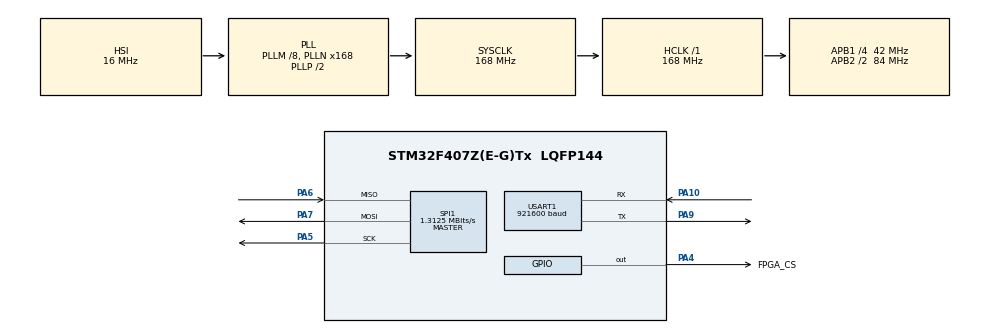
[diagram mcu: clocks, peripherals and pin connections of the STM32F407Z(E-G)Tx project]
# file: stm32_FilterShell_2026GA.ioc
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Mcu.Family=STM32F4
Mcu.Name=STM32F407Z(E-G)Tx
Mcu.Package=LQFP144
NVIC.PriorityGroup=NVIC_PRIORITYGROUP_4
NVIC.USART1_IRQn=true\:5\:0\:false\:false\:true\:true\:true\:true
PA10.Mode=Asynchronous
PA10.Signal=USART1_RX
PA13.Mode=Serial_Wire
PA13.Signal=SYS_JTMS-SWDIO
PA14.Mode=Serial_Wire
PA14.Signal=SYS_JTCK-SWCLK
PA4.GPIO_Label=FPGA_CS
PA4.PinState=GPIO_PIN_SET
PA4.Signal=GPIO_Output
PA5.Mode=Full_Duplex_Master
PA5.Signal=SPI1_SCK
PA6.Mode=Full_Duplex_Master
PA6.Signal=SPI1_MISO
PA7.Mode=Full_Duplex_Master
PA7.Signal=SPI1_MOSI
PA9.Mode=Asynchronous
PA9.Signal=USART1_TX
ProjectManager.HeapSize=0x200
ProjectManager.StackSize=0x1000
ProjectManager.TargetToolchain=MDK-ARM V5.32
RCC.48MHZClocksFreq_Value=48000000
RCC.AHBFreq_Value=168000000
RCC.APB1CLKDivider=RCC_HCLK_DIV4
RCC.APB1Freq_Value=42000000
RCC.APB1TimFreq_Value=84000000
RCC.APB2CLKDivider=RCC_HCLK_DIV2
RCC.APB2Freq_Value=84000000
RCC.APB2TimFreq_Value=168000000
RCC.CortexFreq_Value=168000000
RCC.HCLKFreq_Value=168000000
RCC.HSE_VALUE=25000000
RCC.HSI_VALUE=16000000
RCC.LSE_VALUE=32768
RCC.PLLM=8
RCC.PLLN=168
RCC.PLLQ=7
RCC.SYSCLKFreq_VALUE=168000000
RCC.SYSCLKSource=RCC_SYSCLKSOURCE_PLLCLK
RCC.VCOOutputFreq_Value=336000000
SPI1.BaudRatePrescaler=SPI_BAUDRATEPRESCALER_64
SPI1.CalculateBaudRate=1.3125 MBits/s
SPI1.DataSize=SPI_DATASIZE_16BIT
SPI1.Direction=SPI_DIRECTION_2LINES
SPI1.Mode=SPI_MODE_MASTER
SPI1.VirtualType=VM_MASTER
SYS.Debug=Serial_Wire
USART1.BaudRate=921600
USART1.VirtualMode=VM_ASYNC
board=custom

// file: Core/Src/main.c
/* USER CODE BEGIN Header */
/**
  ******************************************************************************
  * @file           : main.c
  * @brief          : Main program body
  ******************************************************************************
  * @attention
  *
  * Copyright (c) 2026 STMicroelectronics.
  * All rights reserved.
  *
  * This software is licensed under terms that can be found in the LICENSE file
  * in the root directory of this software component.
  * If no LICENSE file comes with this software, it is provided AS-IS.
  *
  ******************************************************************************
  */
/* USER CODE END Header */
#include "main.h"
#include "spi.h"
#include "usart.h"
#include "gpio.h"

/* USER CODE BEGIN Includes */
#include "GSerial.h"
#include "GSignalFlow.h"

/* USER CODE END Includes */

void SystemClock_Config(void);

int main(void)
{

  /* MCU Configuration--------------------------------------------------------*/

  /* Reset of all peripherals, Initializes the Flash interface and the Systick. */
  HAL_Init();

  /* Configure the system clock */
  SystemClock_Config();

  /* Initialize all configured peripherals */
  MX_GPIO_Init();
  MX_SPI1_Init();
  MX_USART1_UART_Init();
  /* USER CODE BEGIN 2 */
  GSerial_Init();
  GSignalFlow_Init();
  /* USER CODE END 2 */

  /* Infinite loop */
  while (1)
  {
    /* USER CODE BEGIN 3 */
    GSignalFlow_Process();
    /* USER CODE END 3 */
  }
}

void SystemClock_Config(void)
{
  RCC_OscInitTypeDef RCC_OscInitStruct = {0};
  RCC_ClkInitTypeDef RCC_ClkInitStruct = {0};

  /** Configure the main internal regulator output voltage
  */
  __HAL_RCC_PWR_CLK_ENABLE();
  __HAL_PWR_VOLTAGESCALING_CONFIG(PWR_REGULATOR_VOLTAGE_SCALE1);

  /** Initializes the RCC Oscillators according to the specified parameters
  * in the RCC_OscInitTypeDef structure.
  */
  RCC_OscInitStruct.OscillatorType = RCC_OSCILLATORTYPE_HSI;
  RCC_OscInitStruct.HSIState = RCC_HSI_ON;
  RCC_OscInitStruct.HSICalibrationValue = RCC_HSICALIBRATION_DEFAULT;
  RCC_OscInitStruct.PLL.PLLState = RCC_PLL_ON;
  RCC_OscInitStruct.PLL.PLLSource = RCC_PLLSOURCE_HSI;
  RCC_OscInitStruct.PLL.PLLM = 8;
  RCC_OscInitStruct.PLL.PLLN = 168;
  RCC_OscInitStruct.PLL.PLLP = RCC_PLLP_DIV2;
  /* PLLQ=7向USB/RNG专用时钟域提供标准48 MHz，CPU主频仍为168 MHz。 */
  RCC_OscInitStruct.PLL.PLLQ = 7;
  if (HAL_RCC_OscConfig(&RCC_OscInitStruct) != HAL_OK)
  {
    Error_Handler();
  }

  /** Initializes the CPU, AHB and APB buses clocks
  */
  RCC_ClkInitStruct.ClockType = RCC_CLOCKTYPE_HCLK|RCC_CLOCKTYPE_SYSCLK
                              |RCC_CLOCKTYPE_PCLK1|RCC_CLOCKTYPE_PCLK2;
  RCC_ClkInitStruct.SYSCLKSource = RCC_SYSCLKSOURCE_PLLCLK;
  RCC_ClkInitStruct.AHBCLKDivider = RCC_SYSCLK_DIV1;
  RCC_ClkInitStruct.APB1CLKDivider = RCC_HCLK_DIV4;
  RCC_ClkInitStruct.APB2CLKDivider = RCC_HCLK_DIV2;

  if (HAL_RCC_ClockConfig(&RCC_ClkInitStruct, FLASH_LATENCY_5) != HAL_OK)
  {
    Error_Handler();
  }
}

void Error_Handler(void)
{
  __disable_irq();
  while (1)
  {
  }
}
